AUTOSAR XML (schema 4-0-3)
package /AUTOSAR_Dcm/SwComponentTypes
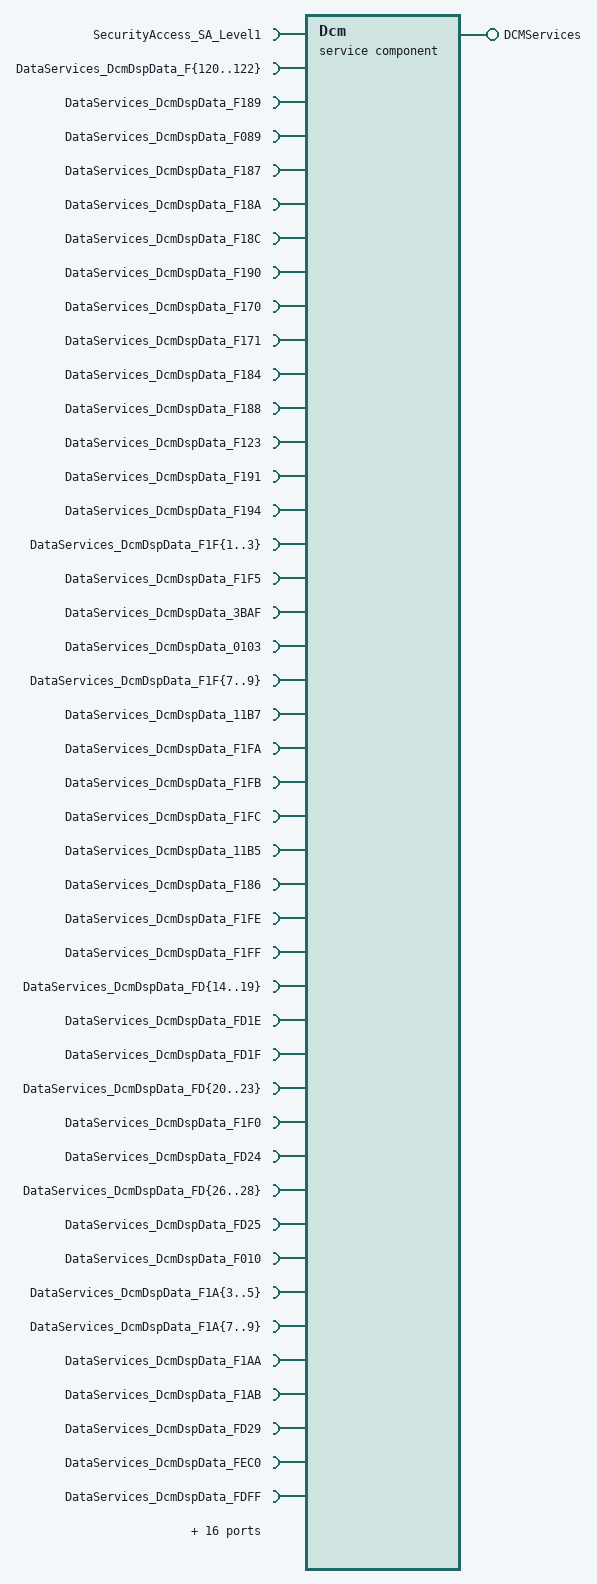
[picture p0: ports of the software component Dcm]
  service sw component type Dcm
    provide port DCMServices: provided-interface=DCMServices
      provided-com-specs:
        operation=GetSecurityLevel, queue-length=1
        operation=GetSesCtrlType, queue-length=1
        operation=GetActiveProtocol, queue-length=1
        operation=ResetToDefaultSession, queue-length=1
    86 x require port:
      SecurityAccess_SA_Level1: required-interface=SecurityAccess_SA_Level1
      DataServices_DcmDspData_F{120..122}: required-interface=DataServices_DcmDspData_F{120..122}
      DataServices_DcmDspData_F189: required-interface=DataServices_DcmDspData_F189
      DataServices_DcmDspData_F089: required-interface=DataServices_DcmDspData_F089
      DataServices_DcmDspData_F187: required-interface=DataServices_DcmDspData_F187
      DataServices_DcmDspData_F18A: required-interface=DataServices_DcmDspData_F18A
      DataServices_DcmDspData_F18C: required-interface=DataServices_DcmDspData_F18C
      DataServices_DcmDspData_F190: required-interface=DataServices_DcmDspData_F190
      DataServices_DcmDspData_F170: required-interface=DataServices_DcmDspData_F170
      DataServices_DcmDspData_F171: required-interface=DataServices_DcmDspData_F171
      DataServices_DcmDspData_F184: required-interface=DataServices_DcmDspData_F184
      DataServices_DcmDspData_F188: required-interface=DataServices_DcmDspData_F188
      DataServices_DcmDspData_F123: required-interface=DataServices_DcmDspData_F123
      DataServices_DcmDspData_F191: required-interface=DataServices_DcmDspData_F191
      DataServices_DcmDspData_F194: required-interface=DataServices_DcmDspData_F194
      DataServices_DcmDspData_F1F{1..3}: required-interface=DataServices_DcmDspData_F1F{1..3}
      DataServices_DcmDspData_F1F5: required-interface=DataServices_DcmDspData_F1F5
      DataServices_DcmDspData_3BAF: required-interface=DataServices_DcmDspData_3BAF
      DataServices_DcmDspData_0103: required-interface=DataServices_DcmDspData_0103
      DataServices_DcmDspData_F1F{7..9}: required-interface=DataServices_DcmDspData_F1F{7..9}
      DataServices_DcmDspData_11B7: required-interface=DataServices_DcmDspData_11B7
      DataServices_DcmDspData_F1FA: required-interface=DataServices_DcmDspData_F1FA
      DataServices_DcmDspData_F1FB: required-interface=DataServices_DcmDspData_F1FB
      DataServices_DcmDspData_F1FC: required-interface=DataServices_DcmDspData_F1FC
      DataServices_DcmDspData_11B5: required-interface=DataServices_DcmDspData_11B5
      DataServices_DcmDspData_F186: required-interface=DataServices_DcmDspData_F186
      DataServices_DcmDspData_F1FE: required-interface=DataServices_DcmDspData_F1FE
      DataServices_DcmDspData_F1FF: required-interface=DataServices_DcmDspData_F1FF
      DataServices_DcmDspData_FD{14..19}: required-interface=DataServices_DcmDspData_FD{14..19}
      DataServices_DcmDspData_FD1E: required-interface=DataServices_DcmDspData_FD1E
      DataServices_DcmDspData_FD1F: required-interface=DataServices_DcmDspData_FD1F
      DataServices_DcmDspData_FD{20..23}: required-interface=DataServices_DcmDspData_FD{20..23}
      DataServices_DcmDspData_F1F0: required-interface=DataServices_DcmDspData_F1F0
      DataServices_DcmDspData_FD24: required-interface=DataServices_DcmDspData_FD24
      DataServices_DcmDspData_FD{26..28}: required-interface=DataServices_DcmDspData_FD{26..28}
      DataServices_DcmDspData_FD25: required-interface=DataServices_DcmDspData_FD25
      DataServices_DcmDspData_F010: required-interface=DataServices_DcmDspData_F010
      DataServices_DcmDspData_F1A{3..5}: required-interface=DataServices_DcmDspData_F1A{3..5}
      DataServices_DcmDspData_F1A{7..9}: required-interface=DataServices_DcmDspData_F1A{7..9}
      DataServices_DcmDspData_F1AA: required-interface=DataServices_DcmDspData_F1AA
      DataServices_DcmDspData_F1AB: required-interface=DataServices_DcmDspData_F1AB
      DataServices_DcmDspData_FD29: required-interface=DataServices_DcmDspData_FD29
      DataServices_DcmDspData_FEC0: required-interface=DataServices_DcmDspData_FEC0
      DataServices_DcmDspData_FDFF: required-interface=DataServices_DcmDspData_FDFF
      DataServices_DcmDspData_F1FD: required-interface=DataServices_DcmDspData_F1FD
      DataServices_DcmDspData_FD00: required-interface=DataServices_DcmDspData_FD00
      DataServices_DcmDspData_FD2A: required-interface=DataServices_DcmDspData_FD2A
      ServiceRequestSupplierNotification_ServiceRequestSupplierNotification: required-interface=ServiceRequestNotification
      RoutineServices_DcmDspRoutine_0x800B: required-interface=RoutineServices_DcmDspRoutine_0x800B
      RoutineServices_DcmDspRoutine_0x800C: required-interface=RoutineServices_DcmDspRoutine_0x800C
      RoutineServices_DcmDspRoutine_0x{0203..0205}: required-interface=RoutineServices_DcmDspRoutine_0x{0203..0205}
      RoutineServices_DcmDspRoutine_0x8010: required-interface=RoutineServices_DcmDspRoutine_0x8010
      RoutineServices_DcmDspRoutine_0x0301: required-interface=RoutineServices_DcmDspRoutine_0x0301
      RoutineServices_DcmDspRoutine_0x0303: required-interface=RoutineServices_DcmDspRoutine_0x0303
      RoutineServices_DcmDspRoutine_0x0302: required-interface=RoutineServices_DcmDspRoutine_0x0302
      RoutineServices_DcmDspRoutine_0x{0305..0309}: required-interface=RoutineServices_DcmDspRoutine_0x{0305..0309}
      RoutineServices_DcmDspRoutine_0x030A: required-interface=RoutineServices_DcmDspRoutine_0x030A
      RoutineServices_DcmDspRoutine_0x8011: required-interface=RoutineServices_DcmDspRoutine_0x8011
      RoutineServices_DcmDspRoutine_0xF012: required-interface=RoutineServices_DcmDspRoutine_0xF012
      RoutineServices_DcmDspRoutine_0xF013: required-interface=RoutineServices_DcmDspRoutine_0xF013
    behavior DcmIntBeh: handle-termination-and-restart=NO-SUPPORT, included-data-type-set=data-type=[Dcm_DidSupportedType, Dcm_ConfirmationStatusType, Dcm_OpStatusType, Dcm_NegativeResponseCodeType]
      4 x operation invoked event:
        EV_GetSecurityLevel: start-on-event=RE_GetSecurityLevel, operation=DCMServices.GetSecurityLevel
        EV_GetSesCtrlType: start-on-event=RE_GetSesCtrlType, operation=DCMServices.GetSesCtrlType
        EV_GetActiveProtocol: start-on-event=RE_GetActiveProtocol, operation=DCMServices.GetActiveProtocol
        EV_ResetToDefaultSession: start-on-event=RE_ResetToDefaultSession, operation=DCMServices.ResetToDefaultSession
      port-api-options:
        enable-take-address=true, indirect-api=false, port=SecurityAccess_SA_Level1
        enable-take-address=true, indirect-api=false, port=DataServices_DcmDspData_F{120..122}
        enable-take-address=true, indirect-api=false, port=DataServices_DcmDspData_F189
        enable-take-address=true, indirect-api=false, port=DataServices_DcmDspData_F089
        enable-take-address=true, indirect-api=false, port=DataServices_DcmDspData_F187
        enable-take-address=true, indirect-api=false, port=DataServices_DcmDspData_F18A
        enable-take-address=true, indirect-api=false, port=DataServices_DcmDspData_F18C
        enable-take-address=true, indirect-api=false, port=DataServices_DcmDspData_F190
        enable-take-address=true, indirect-api=false, port=DataServices_DcmDspData_F170
        enable-take-address=true, indirect-api=false, port=DataServices_DcmDspData_F171
        enable-take-address=true, indirect-api=false, port=DataServices_DcmDspData_F184
        enable-take-address=true, indirect-api=false, port=DataServices_DcmDspData_F188
        enable-take-address=true, indirect-api=false, port=DataServices_DcmDspData_F123
        enable-take-address=true, indirect-api=false, port=DataServices_DcmDspData_F191
        enable-take-address=true, indirect-api=false, port=DataServices_DcmDspData_F194
        enable-take-address=true, indirect-api=false, port=DataServices_DcmDspData_F1F{1..3}
        enable-take-address=true, indirect-api=false, port=DataServices_DcmDspData_F1F5
        enable-take-address=true, indirect-api=false, port=DataServices_DcmDspData_3BAF
        enable-take-address=true, indirect-api=false, port=DataServices_DcmDspData_0103
        enable-take-address=true, indirect-api=false, port=DataServices_DcmDspData_F1F{7..9}
        enable-take-address=true, indirect-api=false, port=DataServices_DcmDspData_11B7
        enable-take-address=true, indirect-api=false, port=DataServices_DcmDspData_F1FA
        enable-take-address=true, indirect-api=false, port=DataServices_DcmDspData_F1FB
        enable-take-address=true, indirect-api=false, port=DataServices_DcmDspData_F1FC
        enable-take-address=true, indirect-api=false, port=DataServices_DcmDspData_11B5
        enable-take-address=true, indirect-api=false, port=DataServices_DcmDspData_F186
        enable-take-address=true, indirect-api=false, port=DataServices_DcmDspData_F1FE
        enable-take-address=true, indirect-api=false, port=DataServices_DcmDspData_F1FF
        enable-take-address=true, indirect-api=false, port=DataServices_DcmDspData_FD{14..19}
        enable-take-address=true, indirect-api=false, port=DataServices_DcmDspData_FD1E
        enable-take-address=true, indirect-api=false, port=DataServices_DcmDspData_FD1F
        enable-take-address=true, indirect-api=false, port=DataServices_DcmDspData_FD{20..23}
        enable-take-address=true, indirect-api=false, port=DataServices_DcmDspData_F1F0
        enable-take-address=true, indirect-api=false, port=DataServices_DcmDspData_FD24
        enable-take-address=true, indirect-api=false, port=DataServices_DcmDspData_FD{26..28}
        enable-take-address=true, indirect-api=false, port=DataServices_DcmDspData_FD25
        enable-take-address=true, indirect-api=false, port=DataServices_DcmDspData_F010
        enable-take-address=true, indirect-api=false, port=DataServices_DcmDspData_F1A{3..5}
        enable-take-address=true, indirect-api=false, port=DataServices_DcmDspData_F1A{7..9}
        enable-take-address=true, indirect-api=false, port=DataServices_DcmDspData_F1AA
        enable-take-address=true, indirect-api=false, port=DataServices_DcmDspData_F1AB
        enable-take-address=true, indirect-api=false, port=DataServices_DcmDspData_FD29
        enable-take-address=true, indirect-api=false, port=DataServices_DcmDspData_FEC0
        enable-take-address=true, indirect-api=false, port=DataServices_DcmDspData_FDFF
        enable-take-address=true, indirect-api=false, port=DataServices_DcmDspData_F1FD
        enable-take-address=true, indirect-api=false, port=DataServices_DcmDspData_FD00
        enable-take-address=true, indirect-api=false, port=DataServices_DcmDspData_FD2A
        enable-take-address=true, indirect-api=false, port=ServiceRequestSupplierNotification_ServiceRequestSupplierNotification
        enable-take-address=true, indirect-api=false, port=RoutineServices_DcmDspRoutine_0x800B
        enable-take-address=true, indirect-api=false, port=RoutineServices_DcmDspRoutine_0x800C
        enable-take-address=true, indirect-api=false, port=RoutineServices_DcmDspRoutine_0x{0203..0205}
        enable-take-address=true, indirect-api=false, port=RoutineServices_DcmDspRoutine_0x8010
        enable-take-address=true, indirect-api=false, port=RoutineServices_DcmDspRoutine_0x0301
        enable-take-address=true, indirect-api=false, port=RoutineServices_DcmDspRoutine_0x0303
        enable-take-address=true, indirect-api=false, port=RoutineServices_DcmDspRoutine_0x0302
        enable-take-address=true, indirect-api=false, port=RoutineServices_DcmDspRoutine_0x{0305..0309}
        enable-take-address=true, indirect-api=false, port=RoutineServices_DcmDspRoutine_0x030A
        enable-take-address=true, indirect-api=false, port=RoutineServices_DcmDspRoutine_0x8011
        enable-take-address=true, indirect-api=false, port=RoutineServices_DcmDspRoutine_0xF012
        enable-take-address=true, indirect-api=false, port=RoutineServices_DcmDspRoutine_0xF013
      5 x runnable, all with sw-addr-method=CODE:
        RE_GetSecurityLevel: can-be-invoked-concurrently=true, symbol=Dcm_GetSecurityLevel
        RE_GetSesCtrlType: can-be-invoked-concurrently=true, symbol=Dcm_GetSesCtrlType
        RE_GetActiveProtocol: can-be-invoked-concurrently=true, symbol=Dcm_GetActiveProtocol
        RE_ResetToDefaultSession: can-be-invoked-concurrently=true, symbol=Dcm_ResetToDefaultSession
        RE_MainFunction: symbol=Dcm_MainFunction
          124 x sync call, all with timeout=0.0:
            sscp_SecurityAccessGetSeed_SA_Level1: operation=SecurityAccess_SA_Level1.GetSeed
            sscp_SecurityAccessCompareKey_SA_Level1: operation=SecurityAccess_SA_Level1.CompareKey
            sscp_SecurityAccessGetSecurityAttemptCounter_SA_Level1: operation=SecurityAccess_SA_Level1.GetSecurityAttemptCounter
            sscp_SecurityAccessSetSecurityAttemptCounter_SA_Level1: operation=SecurityAccess_SA_Level1.SetSecurityAttemptCounter
            sscp_DataServicesReadData_DcmDspData_F{120..122}: operation=DataServices_DcmDspData_F{120..122}.ReadData
            sscp_DataServicesReadData_DcmDspData_F189: operation=DataServices_DcmDspData_F189.ReadData
            sscp_DataServicesWriteData_DcmDspData_F089: operation=DataServices_DcmDspData_F089.WriteData
            sscp_DataServicesReadData_DcmDspData_F089: operation=DataServices_DcmDspData_F089.ReadData
            sscp_DataServicesWriteData_DcmDspData_F187: operation=DataServices_DcmDspData_F187.WriteData
            sscp_DataServicesReadData_DcmDspData_F187: operation=DataServices_DcmDspData_F187.ReadData
            sscp_DataServicesWriteData_DcmDspData_F18A: operation=DataServices_DcmDspData_F18A.WriteData
            sscp_DataServicesReadData_DcmDspData_F18A: operation=DataServices_DcmDspData_F18A.ReadData
            sscp_DataServicesWriteData_DcmDspData_F18C: operation=DataServices_DcmDspData_F18C.WriteData
            sscp_DataServicesReadData_DcmDspData_F18C: operation=DataServices_DcmDspData_F18C.ReadData
            sscp_DataServicesWriteData_DcmDspData_F190: operation=DataServices_DcmDspData_F190.WriteData
            sscp_DataServicesReadData_DcmDspData_F190: operation=DataServices_DcmDspData_F190.ReadData
            sscp_DataServicesReadData_DcmDspData_F170: operation=DataServices_DcmDspData_F170.ReadData
            sscp_DataServicesReadData_DcmDspData_F171: operation=DataServices_DcmDspData_F171.ReadData
            sscp_DataServicesReadData_DcmDspData_F184: operation=DataServices_DcmDspData_F184.ReadData
            sscp_DataServicesReadData_DcmDspData_F188: operation=DataServices_DcmDspData_F188.ReadData
            sscp_DataServicesReadData_DcmDspData_F123: operation=DataServices_DcmDspData_F123.ReadData
            sscp_DataServicesReadData_DcmDspData_F191: operation=DataServices_DcmDspData_F191.ReadData
            sscp_DataServicesReadData_DcmDspData_F194: operation=DataServices_DcmDspData_F194.ReadData
            sscp_DataServicesWriteData_DcmDspData_F1F1: operation=DataServices_DcmDspData_F1F1.WriteData
            sscp_DataServicesReadData_DcmDspData_F1F1: operation=DataServices_DcmDspData_F1F1.ReadData
            sscp_DataServicesWriteData_DcmDspData_F1F2: operation=DataServices_DcmDspData_F1F2.WriteData
            sscp_DataServicesReadData_DcmDspData_F1F2: operation=DataServices_DcmDspData_F1F2.ReadData
            sscp_DataServicesWriteData_DcmDspData_F1F3: operation=DataServices_DcmDspData_F1F3.WriteData
            sscp_DataServicesReadData_DcmDspData_F1F3: operation=DataServices_DcmDspData_F1F3.ReadData
            sscp_DataServicesReadData_DcmDspData_F1F5: operation=DataServices_DcmDspData_F1F5.ReadData
            sscp_DataServicesReadData_DcmDspData_3BAF: operation=DataServices_DcmDspData_3BAF.ReadData
            sscp_DataServicesReadData_DcmDspData_0103: operation=DataServices_DcmDspData_0103.ReadData
            sscp_DataServicesReadData_DcmDspData_F1F{7..9}: operation=DataServices_DcmDspData_F1F{7..9}.ReadData
            sscp_DataServicesReadData_DcmDspData_11B7: operation=DataServices_DcmDspData_11B7.ReadData
            sscp_DataServicesReadData_DcmDspData_F1FA: operation=DataServices_DcmDspData_F1FA.ReadData
            sscp_DataServicesReadData_DcmDspData_F1FB: operation=DataServices_DcmDspData_F1FB.ReadData
            sscp_DataServicesReadData_DcmDspData_F1FC: operation=DataServices_DcmDspData_F1FC.ReadData
            sscp_DataServicesReadData_DcmDspData_11B5: operation=DataServices_DcmDspData_11B5.ReadData
            sscp_DataServicesReadData_DcmDspData_F186: operation=DataServices_DcmDspData_F186.ReadData
            sscp_DataServicesWriteData_DcmDspData_F1FE: operation=DataServices_DcmDspData_F1FE.WriteData
            sscp_DataServicesReadData_DcmDspData_F1FE: operation=DataServices_DcmDspData_F1FE.ReadData
            sscp_DataServicesWriteData_DcmDspData_F1FF: operation=DataServices_DcmDspData_F1FF.WriteData
            sscp_DataServicesReadData_DcmDspData_F1FF: operation=DataServices_DcmDspData_F1FF.ReadData
            sscp_DataServicesReadData_DcmDspData_FD{14..19}: operation=DataServices_DcmDspData_FD{14..19}.ReadData
            sscp_DataServicesReadData_DcmDspData_FD1E: operation=DataServices_DcmDspData_FD1E.ReadData
            sscp_DataServicesReadData_DcmDspData_FD1F: operation=DataServices_DcmDspData_FD1F.ReadData
            sscp_DataServicesReadData_DcmDspData_FD{20..23}: operation=DataServices_DcmDspData_FD{20..23}.ReadData
            sscp_DataServicesWriteData_DcmDspData_F1F0: operation=DataServices_DcmDspData_F1F0.WriteData
            sscp_DataServicesReadData_DcmDspData_F1F0: operation=DataServices_DcmDspData_F1F0.ReadData
            sscp_DataServicesWriteData_DcmDspData_FD24: operation=DataServices_DcmDspData_FD24.WriteData
            sscp_DataServicesReadData_DcmDspData_FD24: operation=DataServices_DcmDspData_FD24.ReadData
            sscp_DataServicesReadData_DcmDspData_FD{26..28}: operation=DataServices_DcmDspData_FD{26..28}.ReadData
            sscp_DataServicesReadData_DcmDspData_FD25: operation=DataServices_DcmDspData_FD25.ReadData
            sscp_DataServicesConditionCheckRead_DcmDspData_F010: operation=DataServices_DcmDspData_F010.ConditionCheckRead
            sscp_DataServicesReadData_DcmDspData_F010: operation=DataServices_DcmDspData_F010.ReadData
            sscp_DataServicesReadData_DcmDspData_F1A{3..5}: operation=DataServices_DcmDspData_F1A{3..5}.ReadData
            sscp_DataServicesReadData_DcmDspData_F1A{7..9}: operation=DataServices_DcmDspData_F1A{7..9}.ReadData
            sscp_DataServicesReadData_DcmDspData_F1AA: operation=DataServices_DcmDspData_F1AA.ReadData
            sscp_DataServicesReadData_DcmDspData_F1AB: operation=DataServices_DcmDspData_F1AB.ReadData
            sscp_DataServicesReadData_DcmDspData_FD29: operation=DataServices_DcmDspData_FD29.ReadData
            sscp_DataServicesReadData_DcmDspData_FEC0: operation=DataServices_DcmDspData_FEC0.ReadData
            sscp_DataServicesWriteData_DcmDspData_FDFF: operation=DataServices_DcmDspData_FDFF.WriteData
            sscp_DataServicesReadData_DcmDspData_FDFF: operation=DataServices_DcmDspData_FDFF.ReadData
            sscp_DataServicesWriteData_DcmDspData_F1FD: operation=DataServices_DcmDspData_F1FD.WriteData
            sscp_DataServicesReadData_DcmDspData_F1FD: operation=DataServices_DcmDspData_F1FD.ReadData
            sscp_DataServicesWriteData_DcmDspData_FD00: operation=DataServices_DcmDspData_FD00.WriteData
            sscp_DataServicesReadData_DcmDspData_FD00: operation=DataServices_DcmDspData_FD00.ReadData
            sscp_DataServicesWriteData_DcmDspData_FD2A: operation=DataServices_DcmDspData_FD2A.WriteData
            sscp_DataServicesReadData_DcmDspData_FD2A: operation=DataServices_DcmDspData_FD2A.ReadData
            sscp_ServiceRequestSupplierNotificationIndication_ServiceRequestSupplierNotification: operation=ServiceRequestSupplierNotification_ServiceRequestSupplierNotification.Indication
            sscp_ServiceRequestSupplierNotificationConfirmation_ServiceRequestSupplierNotification: operation=ServiceRequestSupplierNotification_ServiceRequestSupplierNotification.Confirmation
            sscp_RoutineServicesStart_DcmDspRoutine_0x800B: operation=RoutineServices_DcmDspRoutine_0x800B.Start
            sscp_RoutineServicesRequestResults_DcmDspRoutine_0x800B: operation=RoutineServices_DcmDspRoutine_0x800B.RequestResults
            sscp_RoutineServicesStart_DcmDspRoutine_0x800C: operation=RoutineServices_DcmDspRoutine_0x800C.Start
            sscp_RoutineServicesRequestResults_DcmDspRoutine_0x800C: operation=RoutineServices_DcmDspRoutine_0x800C.RequestResults
            sscp_RoutineServicesStart_DcmDspRoutine_0x{0203..0205}: operation=RoutineServices_DcmDspRoutine_0x{0203..0205}.Start
            sscp_RoutineServicesStart_DcmDspRoutine_0x8010: operation=RoutineServices_DcmDspRoutine_0x8010.Start
            sscp_RoutineServicesRequestResults_DcmDspRoutine_0x8010: operation=RoutineServices_DcmDspRoutine_0x8010.RequestResults
            sscp_RoutineServicesStart_DcmDspRoutine_0x0301: operation=RoutineServices_DcmDspRoutine_0x0301.Start
            sscp_RoutineServicesRequestResults_DcmDspRoutine_0x0301: operation=RoutineServices_DcmDspRoutine_0x0301.RequestResults
            sscp_RoutineServicesStart_DcmDspRoutine_0x0303: operation=RoutineServices_DcmDspRoutine_0x0303.Start
            sscp_RoutineServicesRequestResults_DcmDspRoutine_0x0303: operation=RoutineServices_DcmDspRoutine_0x0303.RequestResults
            sscp_RoutineServicesStart_DcmDspRoutine_0x0302: operation=RoutineServices_DcmDspRoutine_0x0302.Start
            sscp_RoutineServicesRequestResults_DcmDspRoutine_0x0302: operation=RoutineServices_DcmDspRoutine_0x0302.RequestResults
            sscp_RoutineServicesStart_DcmDspRoutine_0x0305: operation=RoutineServices_DcmDspRoutine_0x0305.Start
            sscp_RoutineServicesRequestResults_DcmDspRoutine_0x0305: operation=RoutineServices_DcmDspRoutine_0x0305.RequestResults
            sscp_RoutineServicesStart_DcmDspRoutine_0x0306: operation=RoutineServices_DcmDspRoutine_0x0306.Start
            sscp_RoutineServicesStop_DcmDspRoutine_0x0306: operation=RoutineServices_DcmDspRoutine_0x0306.Stop
            sscp_RoutineServicesRequestResults_DcmDspRoutine_0x0306: operation=RoutineServices_DcmDspRoutine_0x0306.RequestResults
            sscp_RoutineServicesStart_DcmDspRoutine_0x0307: operation=RoutineServices_DcmDspRoutine_0x0307.Start
            sscp_RoutineServicesStop_DcmDspRoutine_0x0307: operation=RoutineServices_DcmDspRoutine_0x0307.Stop
            sscp_RoutineServicesRequestResults_DcmDspRoutine_0x0307: operation=RoutineServices_DcmDspRoutine_0x0307.RequestResults
            sscp_RoutineServicesStart_DcmDspRoutine_0x0308: operation=RoutineServices_DcmDspRoutine_0x0308.Start
            sscp_RoutineServicesRequestResults_DcmDspRoutine_0x0308: operation=RoutineServices_DcmDspRoutine_0x0308.RequestResults
            sscp_RoutineServicesStart_DcmDspRoutine_0x0309: operation=RoutineServices_DcmDspRoutine_0x0309.Start
            sscp_RoutineServicesRequestResults_DcmDspRoutine_0x0309: operation=RoutineServices_DcmDspRoutine_0x0309.RequestResults
            sscp_RoutineServicesStart_DcmDspRoutine_0x030A: operation=RoutineServices_DcmDspRoutine_0x030A.Start
            sscp_RoutineServicesRequestResults_DcmDspRoutine_0x030A: operation=RoutineServices_DcmDspRoutine_0x030A.RequestResults
            sscp_RoutineServicesStart_DcmDspRoutine_0x8011: operation=RoutineServices_DcmDspRoutine_0x8011.Start
            sscp_RoutineServicesRequestResults_DcmDspRoutine_0x8011: operation=RoutineServices_DcmDspRoutine_0x8011.RequestResults
            sscp_RoutineServicesStart_DcmDspRoutine_0xF012: operation=RoutineServices_DcmDspRoutine_0xF012.Start
            sscp_RoutineServicesRequestResults_DcmDspRoutine_0xF012: operation=RoutineServices_DcmDspRoutine_0xF012.RequestResults
            sscp_RoutineServicesStart_DcmDspRoutine_0xF013: operation=RoutineServices_DcmDspRoutine_0xF013.Start
            sscp_RoutineServicesRequestResults_DcmDspRoutine_0xF013: operation=RoutineServices_DcmDspRoutine_0xF013.RequestResults
package /EB_Dcm/SwcImplementations
  swc implementation DcmImpl: programming-language=C, sw-version=5.0.10, vendor-id=1, behavior=DcmIntBeh
    code-descriptors:
      code Code: artifact-descriptors=autosar-engineering-object={short-label=EngObject, category=SWSRC}
    resource consumption Resources
      memory section CODE: sw-addrmethod=CODE
